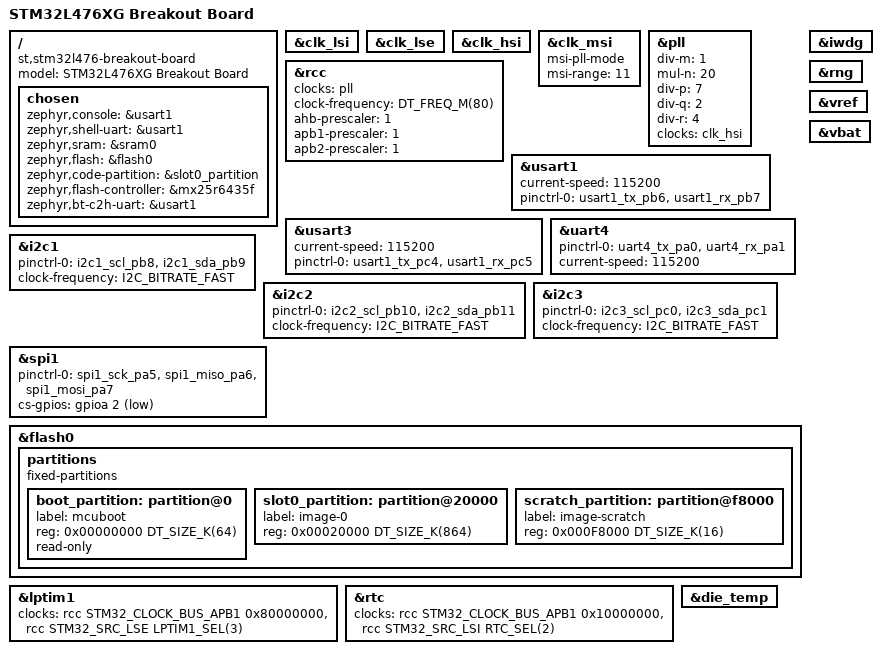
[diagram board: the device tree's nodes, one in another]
/*
 * By Sam Burner 2025/06/18
 *
 * SPDX-License-Identifier: Apache-2.0
 */

 /dts-v1/;
#include <st\l4\stm32l476Xg.dtsi>
#include <st\l4\stm32l476r(c-e-g)tx-pinctrl.dtsi>
#include "arduino_r3_connector.dtsi"
#include <zephyr/dt-bindings/input/input-event-codes.h>

/ {
    model = "STM32L476XG Breakout Board";
    compatible = "st,stm32l476-breakout-board"; /* not sure if the "st," is an issue? possibly defined by vendor in yaml files */

    chosen {
		zephyr,console = &usart1;
		zephyr,shell-uart = &usart1;
		zephyr,sram = &sram0;
		zephyr,flash = &flash0;
		zephyr,code-partition = &slot0_partition;
		zephyr,flash-controller = &mx25r6435f;
		zephyr,bt-c2h-uart = &usart1; /* probably unnecessary */
	};

};

&clk_lsi {
	status = "okay";
};

&clk_lse {
	status = "okay";
};

&clk_hsi {
	status = "okay";
};

/* probably unnecessary, hopefully not a problem */
&clk_msi {
	status = "okay";
	msi-pll-mode;
	msi-range = <11>; /* 48MHz USB bus clk */
};

&pll {
	div-m = <1>;
	mul-n = <20>;
	div-p = <7>;
	div-q = <2>;
	div-r = <4>;
	clocks = <&clk_hsi>;
	status = "okay";
};

&rcc {
	clocks = <&pll>;
	clock-frequency = <DT_FREQ_M(80)>;
	ahb-prescaler = <1>;
	apb1-prescaler = <1>;
	apb2-prescaler = <1>;
};

&usart1 {
	current-speed = <115200>;
	pinctrl-0 = <&usart1_tx_pb6 &usart1_rx_pb7>;
	pinctrl-names = "default";
	status = "okay";
};

&usart3 {
	current-speed = <115200>;
	pinctrl-0 = <&usart1_tx_pc4 &usart1_rx_pc5>;
	pinctrl-names = "default";
	status = "okay";
};

&uart4 {
	pinctrl-0 = <&uart4_tx_pa0 &uart4_rx_pa1>;
	pinctrl-names = "default";
	current-speed = <115200>;
	status = "okay";
};

&i2c1 {
	pinctrl-0 = <&i2c1_scl_pb8 &i2c1_sda_pb9>;
	pinctrl-names = "default";
	status = "okay";
	clock-frequency = <I2C_BITRATE_FAST>;
};

&i2c2 {
	pinctrl-0 = <&i2c2_scl_pb10 &i2c2_sda_pb11>;
	pinctrl-names = "default";
	status = "okay";
	clock-frequency = <I2C_BITRATE_FAST>;
};

&i2c3 {
	pinctrl-0 = <&i2c3_scl_pc0 &i2c3_sda_pc1>;
	pinctrl-names = "default";
	status = "okay";
	clock-frequency = <I2C_BITRATE_FAST>;
};

&spi1 {
	pinctrl-0 = <&spi1_sck_pa5 &spi1_miso_pa6 &spi1_mosi_pa7>;
	pinctrl-names = "default";
	cs-gpios = <&gpioa 2 (GPIO_ACTIVE_LOW | GPIO_PULL_UP)>;
	status = "okay";
};

&flash0 {
	partitions {
		compatible = "fixed-partitions";
		#address-cells = <1>;
		#size-cells = <1>;

		boot_partition: partition@0 {
			label = "mcuboot";
			reg = <0x00000000 DT_SIZE_K(64)>;
			read-only;
		};

		/*
		 * The flash starting at offset 0x10000 and ending at
		 * offset 0x1ffff is reserved for use by the application.
		 */

		slot0_partition: partition@20000 {
			label = "image-0";
			reg = <0x00020000 DT_SIZE_K(864)>;
		};

		scratch_partition: partition@f8000 {
			label = "image-scratch";
			reg = <0x000F8000 DT_SIZE_K(16)>;
		};
	};
};

stm32_lp_tick_source: &lptim1 {
	clocks = <&rcc STM32_CLOCK_BUS_APB1 0x80000000>,
		 <&rcc STM32_SRC_LSE LPTIM1_SEL(3)>;
	status = "okay";
};

&rtc {
	clocks = <&rcc STM32_CLOCK_BUS_APB1 0x10000000>,
		 <&rcc STM32_SRC_LSI RTC_SEL(2)>;
	status = "okay";
};

&iwdg {
	status = "okay";
};

&rng {
	status = "okay";
};

&die_temp {
	status = "okay";
};

&vref {
	status = "okay";
};

&vbat {
	status = "okay";
};



